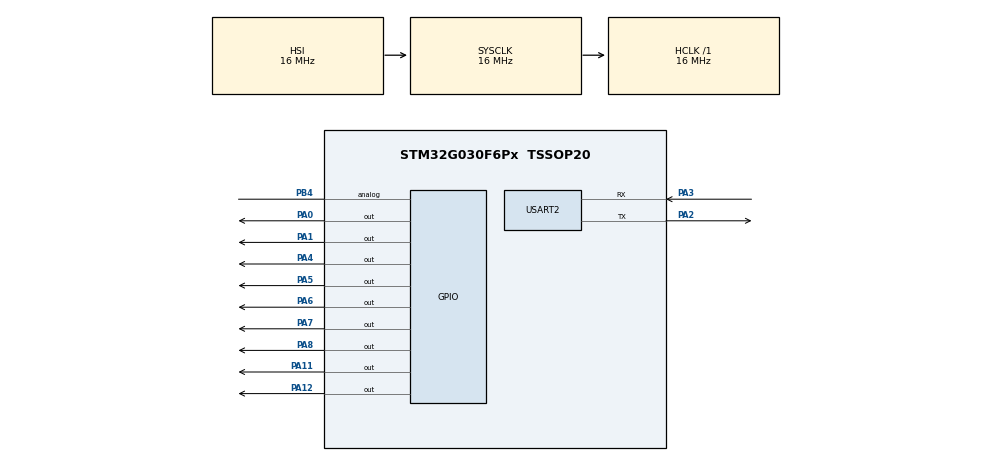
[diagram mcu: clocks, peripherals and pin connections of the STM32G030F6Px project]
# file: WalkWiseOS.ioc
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Mcu.Family=STM32G0
Mcu.Name=STM32G030F6Px
Mcu.Package=TSSOP20
NVIC.USART2_IRQn=true\:0\:0\:false\:false\:true\:true\:true\:true
PA0.Signal=GPIO_Output
PA1.Signal=GPIO_Output
PA11\ [PA9].Signal=GPIO_Output
PA12\ [PA10].Signal=GPIO_Output
PA13.Mode=Serial_Wire
PA13.Signal=SYS_SWDIO
PA14-BOOT0.Mode=Serial_Wire
PA14-BOOT0.Signal=SYS_SWCLK
PA14-BOOT0__PA15.StandardMode=true
PA2.Mode=Asynchronous
PA2.Signal=USART2_TX
PA3.Mode=Asynchronous
PA3.Signal=USART2_RX
PA4.Signal=GPIO_Output
PA5.Signal=GPIO_Output
PA6.Signal=GPIO_Output
PA7.Signal=GPIO_Output
PA8.Signal=GPIO_Output
PB0__PB1__PB2__PA8.StandardMode=true
PB3__PB4__PB5__PB6.StandardMode=true
PB4.Signal=GPIO_Analog
PB7__PB8.StandardMode=true
PC14-OSC32_IN\ (PC14)__PB9.StandardMode=true
ProjectManager.HeapSize=0x200
ProjectManager.StackSize=0x400
ProjectManager.TargetToolchain=STM32CubeIDE
RCC.AHBFreq_Value=16000000
RCC.CortexFreq_Value=16000000
RCC.EXTERNAL_CLOCK_VALUE=12288000
RCC.HCLKFreq_Value=16000000
RCC.HSE_VALUE=8000000
RCC.HSI_VALUE=16000000
RCC.LSE_VALUE=32768
RCC.SYSCLKFreq_VALUE=16000000
RCC.VCOOutputFreq_Value=128000000
USART2.VirtualMode-Asynchronous=VM_ASYNC
board=custom

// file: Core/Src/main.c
/* USER CODE BEGIN Header */
/**
  ******************************************************************************
  * @file           : main.c
  * @brief          : Main program body
  ******************************************************************************
  * @attention
  *
  * Copyright (c) 2024 STMicroelectronics.
  * All rights reserved.
  *
  * This software is licensed under terms that can be found in the LICENSE file
  * in the root directory of this software component.
  * If no LICENSE file comes with this software, it is provided AS-IS.
  *
  ******************************************************************************
  */
/* USER CODE END Header */
#include "main.h"

UART_HandleTypeDef huart2;

void SystemClock_Config(void);
static void MX_GPIO_Init(void);
static void MX_USART2_UART_Init(void);

int main(void)
{

  /* MCU Configuration--------------------------------------------------------*/

  /* Reset of all peripherals, Initializes the Flash interface and the Systick. */
  HAL_Init();

  /* Configure the system clock */
  SystemClock_Config();

  /* Initialize all configured peripherals */
  MX_GPIO_Init();
  MX_USART2_UART_Init();

  /* Infinite loop */
  /* USER CODE BEGIN WHILE */

  HAL_GPIO_WritePin(GPIOA, GPIO_PIN_0, GPIO_PIN_SET); // LED - signaling successful flashing

  while (1)
  {
    /* USER CODE END WHILE */

  }
}

void SystemClock_Config(void)
{
  RCC_OscInitTypeDef RCC_OscInitStruct = {0};
  RCC_ClkInitTypeDef RCC_ClkInitStruct = {0};

  /** Configure the main internal regulator output voltage
  */
  HAL_PWREx_ControlVoltageScaling(PWR_REGULATOR_VOLTAGE_SCALE1);

  /** Initializes the RCC Oscillators according to the specified parameters
  * in the RCC_OscInitTypeDef structure.
  */
  RCC_OscInitStruct.OscillatorType = RCC_OSCILLATORTYPE_HSI;
  RCC_OscInitStruct.HSIState = RCC_HSI_ON;
  RCC_OscInitStruct.HSIDiv = RCC_HSI_DIV1;
  RCC_OscInitStruct.HSICalibrationValue = RCC_HSICALIBRATION_DEFAULT;
  RCC_OscInitStruct.PLL.PLLState = RCC_PLL_NONE;
  if (HAL_RCC_OscConfig(&RCC_OscInitStruct) != HAL_OK)
  {
    Error_Handler();
  }

  /** Initializes the CPU, AHB and APB buses clocks
  */
  RCC_ClkInitStruct.ClockType = RCC_CLOCKTYPE_HCLK|RCC_CLOCKTYPE_SYSCLK
                              |RCC_CLOCKTYPE_PCLK1;
  RCC_ClkInitStruct.SYSCLKSource = RCC_SYSCLKSOURCE_HSI;
  RCC_ClkInitStruct.AHBCLKDivider = RCC_SYSCLK_DIV1;
  RCC_ClkInitStruct.APB1CLKDivider = RCC_HCLK_DIV1;

  if (HAL_RCC_ClockConfig(&RCC_ClkInitStruct, FLASH_LATENCY_0) != HAL_OK)
  {
    Error_Handler();
  }
}

static void MX_USART2_UART_Init(void)
{

  huart2.Instance = USART2;
  huart2.Init.BaudRate = 115200;
  huart2.Init.WordLength = UART_WORDLENGTH_8B;
  huart2.Init.StopBits = UART_STOPBITS_1;
  huart2.Init.Parity = UART_PARITY_NONE;
  huart2.Init.Mode = UART_MODE_TX_RX;
  huart2.Init.HwFlowCtl = UART_HWCONTROL_NONE;
  huart2.Init.OverSampling = UART_OVERSAMPLING_16;
  huart2.Init.OneBitSampling = UART_ONE_BIT_SAMPLE_DISABLE;
  huart2.Init.ClockPrescaler = UART_PRESCALER_DIV1;
  huart2.AdvancedInit.AdvFeatureInit = UART_ADVFEATURE_NO_INIT;
  if (HAL_UART_Init(&huart2) != HAL_OK)
  {
    Error_Handler();
  }

}

static void MX_GPIO_Init(void)
{
  GPIO_InitTypeDef GPIO_InitStruct = {0};

  /* GPIO Ports Clock Enable */
  __HAL_RCC_GPIOA_CLK_ENABLE();
  __HAL_RCC_GPIOB_CLK_ENABLE();

  /*Configure GPIO pin Output Level */
  HAL_GPIO_WritePin(GPIOA, GPIO_PIN_0|GPIO_PIN_1|GPIO_PIN_4|GPIO_PIN_5
                          |GPIO_PIN_6|GPIO_PIN_7|GPIO_PIN_8|GPIO_PIN_11
                          |GPIO_PIN_12, GPIO_PIN_RESET);

  /*Configure GPIO pins : PA0 PA1 PA4 PA5
                           PA6 PA7 PA8 PA11
                           PA12 */
  GPIO_InitStruct.Pin = GPIO_PIN_0|GPIO_PIN_1|GPIO_PIN_4|GPIO_PIN_5
                          |GPIO_PIN_6|GPIO_PIN_7|GPIO_PIN_8|GPIO_PIN_11
                          |GPIO_PIN_12;
  GPIO_InitStruct.Mode = GPIO_MODE_OUTPUT_PP;
  GPIO_InitStruct.Pull = GPIO_NOPULL;
  GPIO_InitStruct.Speed = GPIO_SPEED_FREQ_LOW;
  HAL_GPIO_Init(GPIOA, &GPIO_InitStruct);

  /*Configure GPIO pin : PB4 */
  GPIO_InitStruct.Pin = GPIO_PIN_4;
  GPIO_InitStruct.Mode = GPIO_MODE_ANALOG;
  GPIO_InitStruct.Pull = GPIO_NOPULL;
  HAL_GPIO_Init(GPIOB, &GPIO_InitStruct);

}

void Error_Handler(void)
{
  __disable_irq();
  while (1)
  {
  }
}
